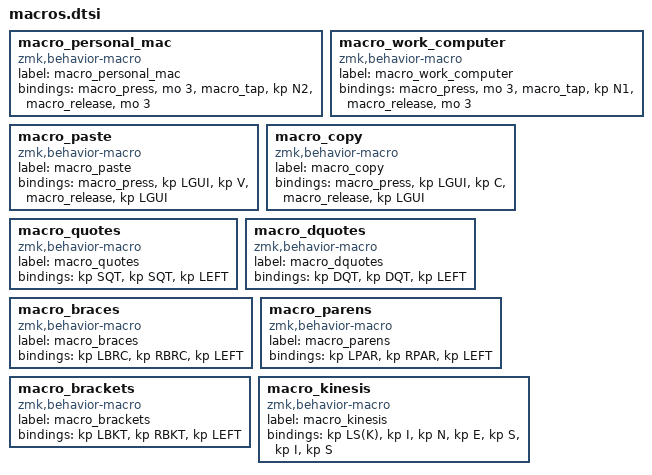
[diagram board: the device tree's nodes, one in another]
macro_personal_mac: macro_personal_mac{
compatible = "zmk,behavior-macro";
label = "macro_personal_mac";
#binding-cells = <0>;
bindings = <&macro_press &mo 3>, <&macro_tap &kp N2>, <&macro_release &mo 3>;
};
macro_work_computer: macro_work_computer{
compatible = "zmk,behavior-macro";
label = "macro_work_computer";
#binding-cells = <0>;
bindings = <&macro_press &mo 3>, <&macro_tap &kp N1>, <&macro_release &mo 3>;
};
macro_paste: macro_paste{
compatible = "zmk,behavior-macro";
label = "macro_paste";
#binding-cells = <0>;
bindings = <&macro_press &kp LGUI>, <&kp V>, <&macro_release &kp LGUI>;
};
macro_copy: macro_copy{
compatible = "zmk,behavior-macro";
label = "macro_copy";
#binding-cells = <0>;
bindings = <&macro_press &kp LGUI>, <&kp C>, <&macro_release &kp LGUI>;
};
macro_quotes: macro_quotes{
compatible = "zmk,behavior-macro";
label = "macro_quotes";
#binding-cells = <0>;
bindings = <&kp SQT>, <&kp SQT>, <&kp LEFT>;
};
macro_dquotes: macro_dquotes{
compatible = "zmk,behavior-macro";
label = "macro_dquotes";
#binding-cells = <0>;
bindings = <&kp DQT>, <&kp DQT>, <&kp LEFT>;
};
macro_braces: macro_braces{
compatible = "zmk,behavior-macro";
label = "macro_braces";
#binding-cells = <0>;
bindings = <&kp LBRC>, <&kp RBRC>, <&kp LEFT>;
};
macro_parens: macro_parens{
compatible = "zmk,behavior-macro";
label = "macro_parens";
#binding-cells = <0>;
bindings = <&kp LPAR>, <&kp RPAR>, <&kp LEFT>;
};
macro_brackets: macro_brackets{
compatible = "zmk,behavior-macro";
label = "macro_brackets";
#binding-cells = <0>;
bindings = <&kp LBKT>, <&kp RBKT>, <&kp LEFT>;
};
macro_kinesis: macro_kinesis{
compatible = "zmk,behavior-macro";
label = "macro_kinesis";
#binding-cells = <0>;
bindings = <&kp LS(K)>, <&kp I>, <&kp N>, <&kp E>, <&kp S>, <&kp I>, <&kp S>;
};
